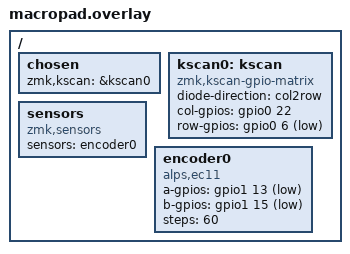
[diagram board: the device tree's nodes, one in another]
#include <dt-bindings/gpio/gpio.h>

/ {
    chosen {
        zmk,kscan = &kscan0;
    };

    kscan0: kscan {
        compatible = "zmk,kscan-gpio-matrix";
        diode-direction = "col2row";
        col-gpios = <&gpio0 22 GPIO_ACTIVE_HIGH>;
        row-gpios = <&gpio0 6 (GPIO_ACTIVE_LOW | GPIO_PULL_UP)>;
    };

    sensors: sensors {
        compatible = "zmk,sensors";
        sensors = <&encoder0>;
    };

    encoder0: encoder0 {
        compatible = "alps,ec11";
        a-gpios = <&gpio1 13 (GPIO_ACTIVE_LOW | GPIO_PULL_UP)>;
        b-gpios = <&gpio1 15 (GPIO_ACTIVE_LOW | GPIO_PULL_UP)>;
        steps = <60>;
        status = "okay";
    };
};
